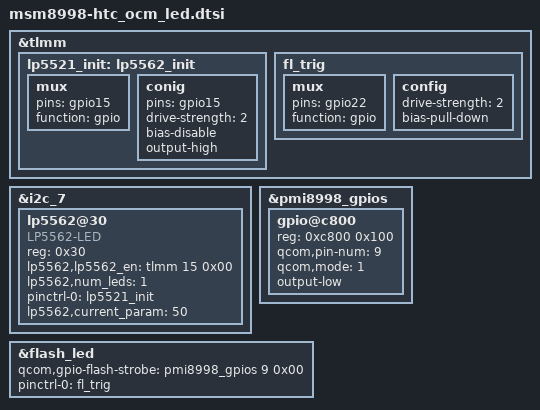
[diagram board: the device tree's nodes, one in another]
&tlmm {
	lp5521_init: lp5562_init {
		mux {
			pins ="gpio15";
			function = "gpio";
		};
		conig {
			pins ="gpio15";
			drive-strength = <2>; // 2 MA
			bias-disable; // No PULL
			output-high;
		};
	};
	fl_trig: fl_trig {
		mux {
			pins = "gpio22";
			function = "gpio";
		};
		config {
			drive-strength = <2>; // 2 MA
			bias-pull-down; // PULL DOWN
		};
	};
};

&i2c_7 {
	lp5562@30 {
		compatible = "LP5562-LED";
		reg = <0x30>;
		lp5562,lp5562_en = <&tlmm 15 0x00>;
//		lp5562,LED_3v3_en = <&pm8998_gpios 6 0x00>; USB config 3V3 in SBL
		lp5562,num_leds = <1>;
		pinctrl-names = "lp5562_init";
		pinctrl-0 = <&lp5521_init>;
		lp5562,current_param = <50>;
	};
};

&pmi8998_gpios {
	gpio@c800 {
		reg = <0xc800 0x100>;
		qcom,pin-num = <9>;
		qcom,mode = <1>;
		output-low;
		status = "okay";
	};
};

&flash_led {
	qcom,gpio-flash-strobe = <&pmi8998_gpios 9 0x00>;
	pinctrl-names = "fl_trig";
	pinctrl-0 = <&fl_trig>;
};
